VERSION ""

NS_ :

BS_:

BU_:

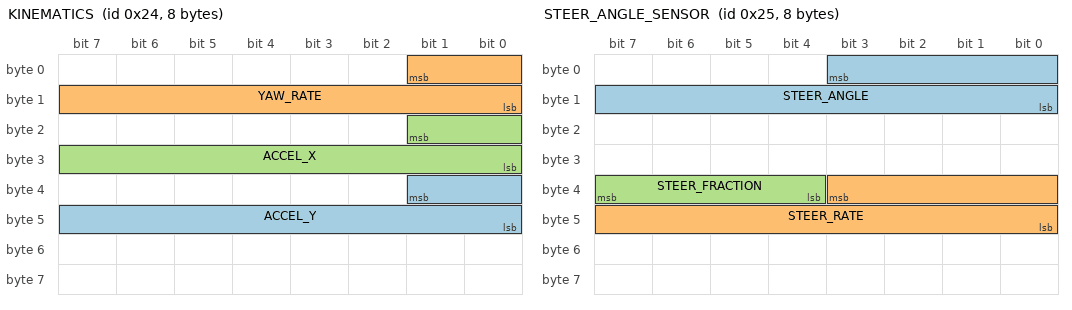
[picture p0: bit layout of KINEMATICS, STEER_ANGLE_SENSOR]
BO_ 36 KINEMATICS: 8 XXX
 SG_ ACCEL_Y : 33|10@0+ (0.03589,-18.375) [-18.375|18.375] "m/s^2" XXX
 SG_ YAW_RATE : 1|10@0+ (0.244,-125) [-125|125] "deg/s" XXX
 SG_ ACCEL_X : 17|10@0+ (0.03589,-18.375) [-18.375|18.375] "m/s^2" XXX

BO_ 37 STEER_ANGLE_SENSOR: 8 XXX
 SG_ STEER_ANGLE : 3|12@0- (0.0573,0) [-500|500] "deg" XXX
 SG_ STEER_RATE : 35|12@0- (1,0) [-2000|2000] "deg/s" XXX
 SG_ STEER_FRACTION : 39|4@0- (0.1,0) [-0.8|0.7] "deg" XXX

BO_ 166 BRAKE_MODULE: 8 XXX
 SG_ BRAKE_PRESSURE : 0|9@0+ (1,0) [0|511] "" XXX
 SG_ BRAKE_PRESSED : 5|1@0+ (1,0) [0|1] "" XXX

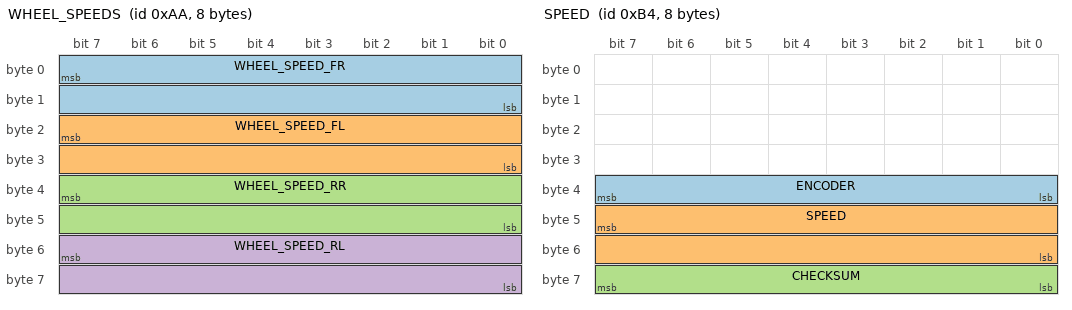
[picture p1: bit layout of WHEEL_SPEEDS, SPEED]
BO_ 170 WHEEL_SPEEDS: 8 XXX
 SG_ WHEEL_SPEED_FR : 7|16@0+ (0.01,0) [0|250] "km/h" XXX
 SG_ WHEEL_SPEED_FL : 23|16@0+ (0.01,0) [0|250] "km/h" XXX
 SG_ WHEEL_SPEED_RR : 39|16@0+ (0.01,0) [0|250] "km/h" XXX
 SG_ WHEEL_SPEED_RL : 55|16@0+ (0.01,0) [0|250] "km/h" XXX

BO_ 180 SPEED: 8 XXX
 SG_ ENCODER : 39|8@0+ (1,0) [0|255] "" XXX
 SG_ SPEED : 47|16@0+ (0.01,0) [0|250] "km/h" XXX
 SG_ CHECKSUM : 63|8@0+ (1,0) [0|255] "" XXX

BO_ 295 GEAR_PACKET: 8 XXX
 SG_ GEAR : 13|6@0+ (1,0) [0|63] "" XXX
 SG_ SPORT_MODE : 2|1@0+ (1,0) [0|1] "" XXX

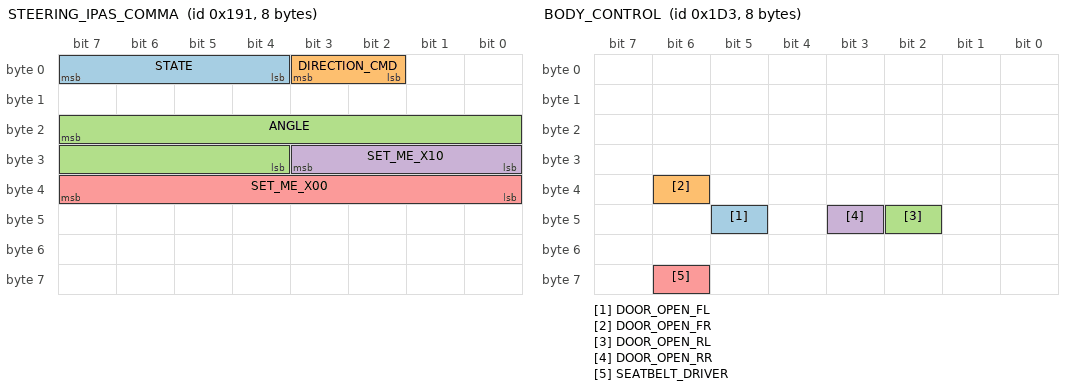
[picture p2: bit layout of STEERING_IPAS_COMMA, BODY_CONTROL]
BO_ 401 STEERING_IPAS_COMMA: 8 XXX
 SG_ STATE : 7|4@0+ (1,0) [0|15] "" XXX
 SG_ DIRECTION_CMD : 3|2@0+ (1,0) [0|3] "" XXX
 SG_ ANGLE : 23|12@0- (1.5,0) [-1500|1500] "deg" XXX
 SG_ SET_ME_X10 : 27|4@0+ (1,0) [0|15] "" XXX
 SG_ SET_ME_X00 : 39|8@0+ (1,0) [0|255] "" XXX

BO_ 466 LIGHT_STALK: 8 XXX
 SG_ TURN_SIGNALS : 5|2@0+ (1,0) [0|3] "" XXX
 SG_ HIGH_BEAMS : 30|1@0+ (1,0) [0|1] "" XXX

BO_ 467 BODY_CONTROL: 8 XXX
 SG_ DOOR_OPEN_FL : 45|1@0+ (1,0) [0|1] "" XXX
 SG_ DOOR_OPEN_FR : 38|1@0+ (1,0) [0|1] "" XXX
 SG_ DOOR_OPEN_RL : 42|1@0+ (1,0) [0|1] "" XXX
 SG_ DOOR_OPEN_RR : 43|1@0+ (1,0) [0|1] "" XXX
 SG_ SEATBELT_DRIVER : 62|1@0+ (1,0) [0|1] "" XXX

BO_ 513 GAS_PEDAL: 8 XXX
 SG_ GAS_RELEASED : 4|1@0+ (1,0) [0|1] "" XXX
 SG_ GAS_PEDAL : 55|8@0+ (0.005,0) [0|1] "" XXX

BO_ 552 ENGINE_TEMP: 8 XXX
 SG_ ENGINE_TEMP : 7|8@0+ (1,-40) [-40|215] "degC" XXX

BO_ 560 BLINKERS_STATE: 8 XXX
 SG_ TURN_SIGNALS : 7|8@0+ (1,0) [0|255] "" XXX
 SG_ HAZARDS : 13|1@0+ (1,0) [0|1] "" XXX

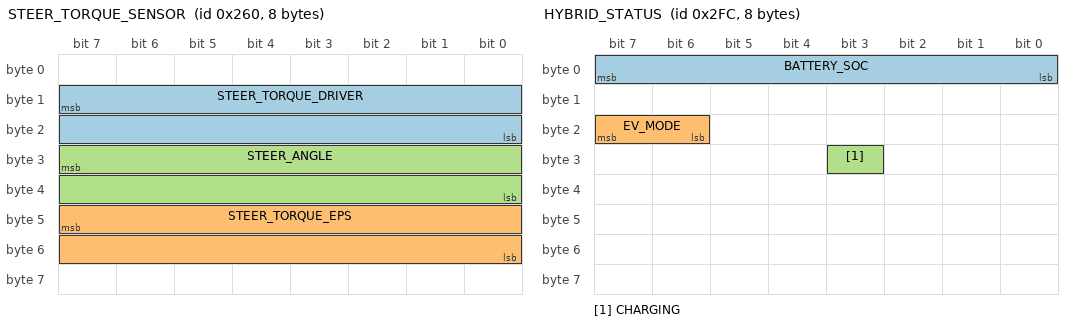
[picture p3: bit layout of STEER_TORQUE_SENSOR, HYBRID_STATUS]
BO_ 608 STEER_TORQUE_SENSOR: 8 XXX
 SG_ STEER_TORQUE_DRIVER : 15|16@0- (1,0) [-32768|32767] "" XXX
 SG_ STEER_TORQUE_EPS : 47|16@0- (1,0) [-32768|32767] "" XXX
 SG_ STEER_ANGLE : 31|16@0- (0.0573,0) [-500|500] "deg" XXX

BO_ 610 EPS_STATUS: 8 XXX
 SG_ IPAS_STATE : 3|4@0+ (1,0) [0|15] "" XXX
 SG_ LKA_STATE : 31|8@0+ (1,0) [0|255] "" XXX

BO_ 614 STEERING_LKA: 8 XXX
 SG_ LKA_STATE : 7|8@0+ (1,0) [0|255] "" XXX
 SG_ STEER_REQUEST : 0|1@0+ (1,0) [0|1] "" XXX
 SG_ STEER_TORQUE_CMD : 15|16@0- (1,0) [-1500|1500] "" XXX
 SG_ SET_ME_1 : 29|1@0+ (1,0) [0|1] "" XXX

BO_ 705 GAS_PEDAL_HYBRID: 8 XXX
 SG_ GAS_PEDAL : 7|8@0+ (0.005,0) [0|1] "" XXX

BO_ 740 STEERING_LKA_2: 8 XXX
 SG_ TORQUE_CMD : 7|16@0- (1,0) [-1500|1500] "" XXX
 SG_ LKA_ACTIVE : 31|1@0+ (1,0) [0|1] "" XXX

BO_ 742 LEAD_INFO: 8 XXX
 SG_ LEAD_REL_SPEED : 23|12@0- (0.025,0) [-50|50] "m/s" XXX
 SG_ LEAD_LONG_DIST : 7|13@0+ (0.05,0) [0|300] "m" XXX

BO_ 764 HYBRID_STATUS: 8 XXX
 SG_ BATTERY_SOC : 7|8@0+ (0.5,0) [0|100] "%" XXX
 SG_ EV_MODE : 23|2@0+ (1,0) [0|3] "" XXX
 SG_ CHARGING : 27|1@0+ (1,0) [0|1] "" XXX

BO_ 800 ENGINE_STATUS: 8 XXX
 SG_ ENGINE_RPM : 7|16@0+ (0.78125,0) [0|8000] "rpm" XXX
 SG_ ENGINE_RUNNING : 30|1@0+ (1,0) [0|1] "" XXX

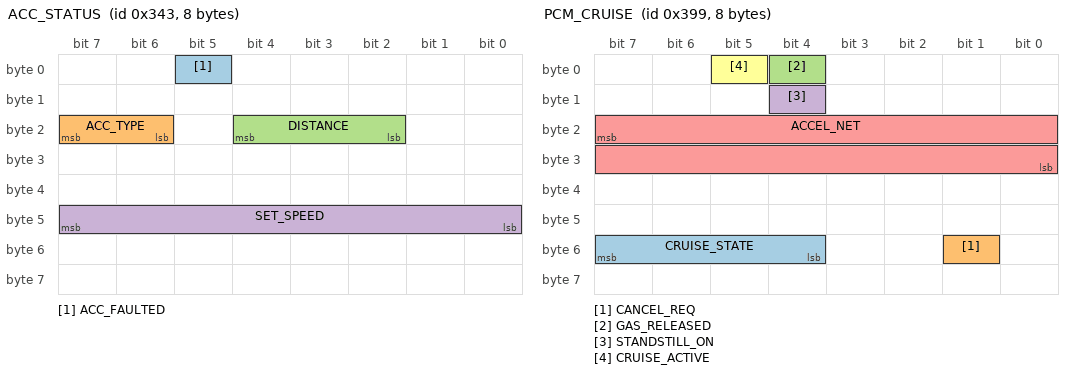
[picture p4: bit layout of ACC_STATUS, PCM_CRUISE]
BO_ 835 ACC_STATUS: 8 XXX
 SG_ ACC_FAULTED : 5|1@0+ (1,0) [0|1] "" XXX
 SG_ ACC_TYPE : 23|2@0+ (1,0) [0|3] "" XXX
 SG_ DISTANCE : 20|3@0+ (1,0) [0|7] "" XXX
 SG_ SET_SPEED : 47|8@0+ (1,0) [0|255] "km/h" XXX

BO_ 921 PCM_CRUISE: 8 XXX
 SG_ CRUISE_STATE : 55|4@0+ (1,0) [0|15] "" XXX
 SG_ CANCEL_REQ : 49|1@0+ (1,0) [0|1] "" XXX
 SG_ GAS_RELEASED : 4|1@0+ (1,0) [0|1] "" XXX
 SG_ STANDSTILL_ON : 12|1@0+ (1,0) [0|1] "" XXX
 SG_ ACCEL_NET : 23|16@0- (0.001,0) [-20|20] "m/s^2" XXX
 SG_ CRUISE_ACTIVE : 5|1@0+ (1,0) [0|1] "" XXX

BO_ 956 GEAR_PACKET_2: 8 XXX
 SG_ GEAR : 5|3@0+ (1,0) [0|7] "" XXX
 SG_ SPORT_MODE_ON : 3|1@0+ (1,0) [0|1] "" XXX

BO_ 1014 BSM_STATUS: 8 XXX
 SG_ BSM_LEFT : 5|1@0+ (1,0) [0|1] "" XXX
 SG_ BSM_RIGHT : 4|1@0+ (1,0) [0|1] "" XXX

BO_ 1042 FUEL_STATUS: 8 XXX
 SG_ FUEL_LEVEL : 7|8@0+ (0.5,0) [0|100] "%" XXX
 SG_ FUEL_LOW_WARNING : 15|1@0+ (1,0) [0|1] "" XXX

BO_ 1553 UI_SETTING: 8 XXX
 SG_ UNITS : 26|2@0+ (1,0) [0|3] "" XXX

VAL_ 295 GEAR 0 "P" 1 "R" 2 "N" 3 "D" 4 "B" ;
VAL_ 956 GEAR 0 "P" 1 "R" 2 "N" 3 "D" 4 "B" ;
VAL_ 466 TURN_SIGNALS 0 "None" 1 "Left" 2 "Right" ;
VAL_ 764 EV_MODE 0 "Normal" 1 "EV" 2 "ECO" 3 "Power" ;
